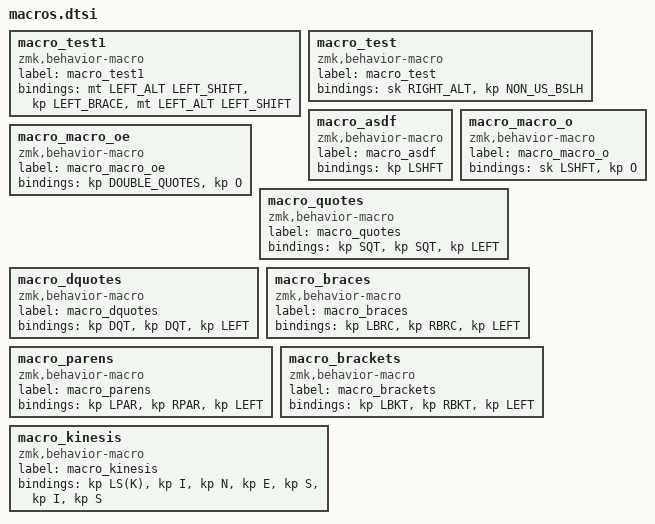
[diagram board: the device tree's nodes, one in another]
macro_test1: macro_test1{
compatible = "zmk,behavior-macro";
label = "macro_test1";
#binding-cells = <0>;
bindings = <&mt LEFT_ALT LEFT_SHIFT>, <&kp LEFT_BRACE>, <&mt LEFT_ALT LEFT_SHIFT>;
};
macro_test: macro_test{
compatible = "zmk,behavior-macro";
label = "macro_test";
#binding-cells = <0>;
bindings = <&sk RIGHT_ALT>, <&kp NON_US_BSLH>;
};
macro_asdf: macro_asdf{
compatible = "zmk,behavior-macro";
label = "macro_asdf";
#binding-cells = <0>;
bindings = <&kp LSHFT>;
};
macro_macro_o: macro_macro_o{
compatible = "zmk,behavior-macro";
label = "macro_macro_o";
#binding-cells = <0>;
bindings = <&sk LSHFT>, <&kp O>;
};
macro_macro_oe: macro_macro_oe{
compatible = "zmk,behavior-macro";
label = "macro_macro_oe";
#binding-cells = <0>;
bindings = <&kp DOUBLE_QUOTES>, <&kp O>;
};
macro_quotes: macro_quotes{
compatible = "zmk,behavior-macro";
label = "macro_quotes";
#binding-cells = <0>;
bindings = <&kp SQT>, <&kp SQT>, <&kp LEFT>;
};
macro_dquotes: macro_dquotes{
compatible = "zmk,behavior-macro";
label = "macro_dquotes";
#binding-cells = <0>;
bindings = <&kp DQT>, <&kp DQT>, <&kp LEFT>;
};
macro_braces: macro_braces{
compatible = "zmk,behavior-macro";
label = "macro_braces";
#binding-cells = <0>;
bindings = <&kp LBRC>, <&kp RBRC>, <&kp LEFT>;
};
macro_parens: macro_parens{
compatible = "zmk,behavior-macro";
label = "macro_parens";
#binding-cells = <0>;
bindings = <&kp LPAR>, <&kp RPAR>, <&kp LEFT>;
};
macro_brackets: macro_brackets{
compatible = "zmk,behavior-macro";
label = "macro_brackets";
#binding-cells = <0>;
bindings = <&kp LBKT>, <&kp RBKT>, <&kp LEFT>;
};
macro_kinesis: macro_kinesis{
compatible = "zmk,behavior-macro";
label = "macro_kinesis";
#binding-cells = <0>;
bindings = <&kp LS(K)>, <&kp I>, <&kp N>, <&kp E>, <&kp S>, <&kp I>, <&kp S>;
};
